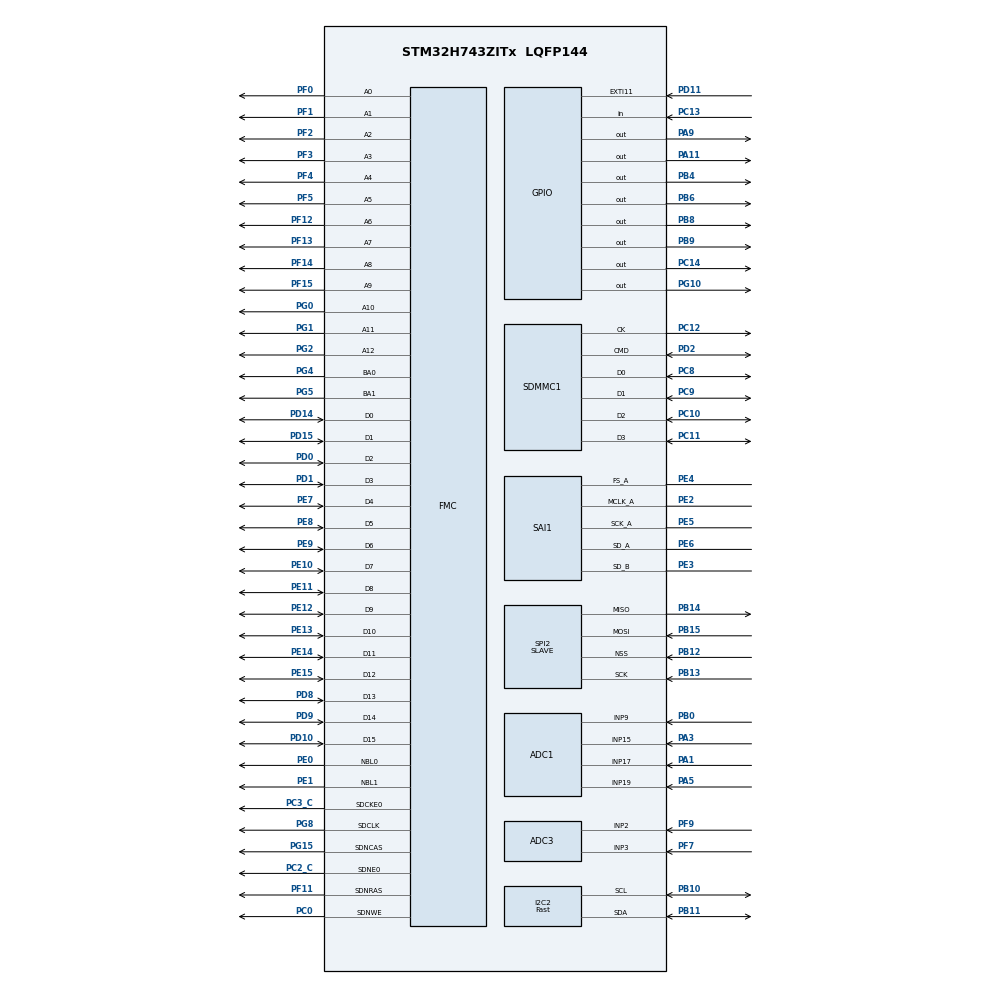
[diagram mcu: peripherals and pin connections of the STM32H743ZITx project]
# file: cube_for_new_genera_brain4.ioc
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Bdma.ADC3.0.PeriphInc=DMA_PINC_DISABLE
Bdma.Request0=ADC3
PC10.GPIO_PuPd=GPIO_PULLUP
FATFS._USE_LFN=1
FMC.SDClockPeriod1=FMC_SDRAM_CLOCK_PERIOD_3
SH.FMC_A0.0=FMC_A0,13b-sda1
FATFS0.BSP.api=Unknown
PG8.Signal=FMC_SDCLK
PG0.Signal=FMC_A10
RCC.PLLFRACN=0
PC3_C.Mode=SdramChipSelect1_1
ADC1.Rank-17\#ChannelRegularConversion=2
SAI1.Instance-SAI_A_MasterWithClock=SAI$Index_Block_A
Dma.SPI2_TX.4.RequestNumber=1
SH.FMC_D5_DA5.0=FMC_D5,sd-16b-d1
Dma.SPI2_RX.1.Mode=DMA_CIRCULAR
Bdma.ADC3.0.Instance=BDMA_Channel0
Dma.SPI2_TX.4.PeriphDataAlignment=DMA_PDATAALIGN_BYTE
SH.FMC_D9_DA9.0=FMC_D9,sd-16b-d1
Dma.SPI2_RX.1.PeriphDataAlignment=DMA_PDATAALIGN_BYTE
ADC1.Offset-17\#ChannelRegularConversion=32768
PF7.Signal=ADC3_INP3
SH.FMC_SDNWE.0=FMC_SDNWE,13b-sda1
Bdma.ADC3.0.SignalID=NONE
RCC.ADCCLockSelection=RCC_ADCCLKSOURCE_CLKP
SH.FMC_D11_DA11.0=FMC_D11,sd-16b-d1
SAI1.BasicProtocol-SAI_B_SyncSlave=SAI_I2S_STANDARD
I2C2.I2C_Speed_Mode=I2C_Fast
PB6.Signal=GPIO_Output
Dma.ADC1.0.Direction=DMA_PERIPH_TO_MEMORY
PD0.Signal=FMC_D2_DA2
SAI1.AudioMode-SAI_A_MasterWithClock=SAI_MODEMASTER_TX
PD8.Signal=FMC_D13_DA13
PE1.Signal=FMC_NBL1
Dma.ADC1.0.MemDataAlignment=DMA_MDATAALIGN_WORD
FATFS0.BSP.ip=GPIO
FMC.SelfRefreshTime1=4
Dma.SPI2_TX.4.EventEnable=DISABLE
Dma.SPI2_RX.1.FIFOMode=DMA_FIFOMODE_ENABLE
ADC1.Channel-19\#ChannelRegularConversion=ADC_CHANNEL_15
RCC.SAI1CLockSelection=RCC_SAI1CLKSOURCE_PLL2
PE9.Signal=FMC_D6_DA6
ADC1.OffsetNumber-19\#ChannelRegularConversion=ADC_OFFSET_NONE
Dma.SAI1_B.3.Direction=DMA_PERIPH_TO_MEMORY
SH.FMC_A2.0=FMC_A2,13b-sda1
PB14.Mode=Full_Duplex_Slave
PC9.Mode=SD_4_bits_Wide_bus
SH.FMC_D1_DA1.0=FMC_D1,sd-16b-d1
Mcu.Package=LQFP144
PB9.Signal=GPIO_Output
SAI1.AudioFrequency-SAI_A_MasterWithClock=SAI_AUDIO_FREQUENCY_48K
Dma.SAI1_B.3.Instance=DMA1_Stream2
SPI2.Mode=SPI_MODE_SLAVE
ADC1.OversamplingMode=ENABLE
RCC.PLL3FRACN=0
Dma.SAI1_A.2.PeriphBurst=DMA_PBURST_SINGLE
Dma.SPI2_RX.1.Instance=DMA1_Stream3
FMC.WriteRecoveryTime1=2
PC11.Mode=SD_4_bits_Wide_bus
FMC.RowCycleDelay1=6
PB13.Mode=Full_Duplex_Slave
ADC3.OffsetNumber-2\#ChannelRegularConversion=ADC_OFFSET_NONE
ADC1.EOCSelection=ADC_EOC_SEQ_CONV
PD15.Signal=FMC_D1_DA1
ADC1.SamplingTime-19\#ChannelRegularConversion=ADC_SAMPLETIME_32CYCLES_5
PC8.GPIO_Mode=GPIO_MODE_AF_PP
Dma.SPI2_TX.4.SignalID=NONE
FATFS0.BSP.STBoard=false
SH.FMC_A4.0=FMC_A4,13b-sda1
ADC3.OffsetNumber-1\#ChannelRegularConversion=ADC_OFFSET_NONE
Dma.SPI2_TX.4.Direction=DMA_MEMORY_TO_PERIPH
ADC1.Offset-18\#ChannelRegularConversion=32768
SAI1.MClockEnable-SAI_A_MasterWithClock=SAI_MASTERCLOCK_ENABLE
PG5.Signal=FMC_A15_BA1
SH.FMC_D10_DA10.0=FMC_D10,sd-16b-d1
PC13.Signal=GPIO_Input
FATFS0.BSP.mode=Input
Dma.SPI2_TX.4.FIFOThreshold=DMA_FIFO_THRESHOLD_1QUARTERFULL
SAI1.ErrorAudioFreq-SAI_A_MasterWithClock=-0.01 %
Dma.SPI2_TX.4.SyncSignalID=NONE
Dma.SAI1_A.2.SyncRequestNumber=1
Dma.SAI1_A.2.MemInc=DMA_MINC_ENABLE
SH.ADCx_INP9.0=ADC1_INP9,IN9-Single-Ended
Dma.SPI2_RX.1.SyncSignalID=NONE
Dma.SAI1_A.2.PeriphInc=DMA_PINC_DISABLE
Bdma.ADC3.0.SyncSignalID=NONE
PD10.Signal=FMC_D15_DA15
PC10.GPIO_Mode=GPIO_MODE_AF_PP
Dma.SPI2_TX.4.SyncEnable=DISABLE
ADC1.Channel-18\#ChannelRegularConversion=ADC_CHANNEL_17
Dma.ADC1.0.Priority=DMA_PRIORITY_HIGH
PB13.GPIO_Speed=GPIO_SPEED_FREQ_HIGH
Dma.SAI1_A.2.MemDataAlignment=DMA_MDATAALIGN_WORD
SAI1.VirtualMode-SAI_A_MasterWithClock=VM_MASTER
VP_SAI1_VP_$IpInstance_SAIB_SAI_BASIC.Mode=SAI_B_BASIC
PB14.Signal=SPI2_MISO
PA5.Signal=ADCx_INP19
PC12.Mode=SD_4_bits_Wide_bus
FMC.ReadBurst1=FMC_SDRAM_RBURST_ENABLE
SH.FMC_A6.0=FMC_A6,13b-sda1
PE14.Signal=FMC_D11_DA11
PE6.Mode=SAI_A_MasterWithClock
PC9.GPIO_PuPd=GPIO_PULLUP
SAI1.FIFOThreshold-SAI_A_MasterWithClock=SAI_FIFOTHRESHOLD_FULL
PF13.Signal=FMC_A7
PC8.Mode=SD_4_bits_Wide_bus
PC8.GPIO_PuPd=GPIO_PULLUP
ADC3.Rank-1\#ChannelRegularConversion=1
ADC1.Rank-16\#ChannelRegularConversion=1
ADC1.master=1
Bdma.ADC3.0.MemInc=DMA_MINC_ENABLE
Dma.ADC1.0.RequestNumber=1
Dma.SAI1_B.3.SignalID=NONE
ProjectManager.HeapSize=0x3000
ADC3.EOCSelection=ADC_EOC_SEQ_CONV
SAI1.VirtualProtocol-SAI_B_BASIC=VM_BASIC_PROTOCOL
NVIC.PriorityGroup=NVIC_PRIORITYGROUP_4
ADC1.ConversionDataManagement=ADC_CONVERSIONDATA_DMA_CIRCULAR
PE3.Signal=SAI1_SD_B
PF4.Signal=FMC_A4
PD2.Signal=SDMMC1_CMD
ADC1.SamplingTime-18\#ChannelRegularConversion=ADC_SAMPLETIME_32CYCLES_5
Dma.SPI2_RX.1.MemInc=DMA_MINC_ENABLE
FATFS0.BSP.name=Detect_SDIO
Mcu.Family=STM32H7
SPI2.VirtualNSS=VM_NSSHARD
SH.FMC_A8.0=FMC_A8,13b-sda1
ADC1.Overrun=ADC_OVR_DATA_PRESERVED
ADC1.ContinuousConvMode=ENABLE
SH.FMC_D14_DA14.0=FMC_D14,sd-16b-d1
PH0-OSC_IN\ (PH0).Signal=RCC_OSC_IN
PG2.Signal=FMC_A12
ADC1.Channel-17\#ChannelRegularConversion=ADC_CHANNEL_19
Dma.ADC1.0.Polarity=HAL_DMAMUX_REQ_GEN_RISING
SAI1.VirtualProtocol-SAI_A_BASIC=VM_BASIC_PROTOCOL
PE2.GPIO_Speed=GPIO_SPEED_FREQ_VERY_HIGH
PD2.GPIO_Mode=GPIO_MODE_AF_PP
RCC.PLL2FRACN=0
SH.FMC_A14_BA0.0=FMC_BA0,FourSdramBanks1
SH.FMC_A11.0=FMC_A11,13b-sda1
PB15.Signal=SPI2_MOSI
Bdma.ADC3.0.SyncPolarity=HAL_DMAMUX_SYNC_NO_EVENT
PG15.Signal=FMC_SDNCAS
Dma.SPI2_RX.1.Direction=DMA_PERIPH_TO_MEMORY
ADC3.Rank-2\#ChannelRegularConversion=2
NVIC.BDMA_Channel0_IRQn=true\:0\:0\:false\:false\:true\:false\:true
PC11.GPIO_PuPd=GPIO_PULLUP
SAI1.VirtualMode-SAI_B_SyncSlave=VM_SLAVE
ADC1.Offset-19\#ChannelRegularConversion=32768
SH.FMC_NBL1.0=FMC_NBL1,Sd2ByteEnable1
PH1-OSC_OUT\ (PH1).Mode=HSE-External-Oscillator
FMC.ExitSelfRefreshDelay1=6
Dma.ADC1.0.PeriphBurst=DMA_PBURST_SINGLE
PF9.Mode=IN2-Single-Ended
PF11.Signal=FMC_SDNRAS
PC13.GPIO_PuPd=GPIO_PULLDOWN
SAI1.InitProtocol-SAI_A_MasterWithClock=Enable
Dma.SAI1_A.2.EventEnable=DISABLE
Dma.SAI1_A.2.Direction=DMA_MEMORY_TO_PERIPH
PB12.Mode=NSS_Signal_Hard_Input
ADC1.SamplingTime-17\#ChannelRegularConversion=ADC_SAMPLETIME_32CYCLES_5
Dma.SPI2_RX.1.FIFOThreshold=DMA_FIFO_THRESHOLD_HALFFULL
Dma.Request2=SAI1_A
Dma.Request1=SPI2_RX
Dma.Request4=SPI2_TX
Dma.Request3=SAI1_B
NVIC.DMA1_Stream0_IRQn=true\:1\:0\:true\:false\:true\:false\:true
PE7.Signal=FMC_D4_DA4
Dma.Request0=ADC1
PA3.Signal=ADCx_INP15
Dma.SAI1_B.3.EventEnable=DISABLE
ADC1.OffsetNumber-17\#ChannelRegularConversion=ADC_OFFSET_NONE
Dma.SAI1_B.3.MemInc=DMA_MINC_ENABLE
PC11.Signal=SDMMC1_D3
ADC1.Rank-18\#ChannelRegularConversion=3
PC8.Signal=SDMMC1_D0
Dma.SAI1_A.2.Instance=DMA1_Stream1
PC10.Mode=SD_4_bits_Wide_bus
Dma.SPI2_TX.4.SyncRequestNumber=1
PD9.Signal=FMC_D14_DA14
SAI1.FIFOThreshold-SAI_B_SyncSlave=SAI_FIFOTHRESHOLD_FULL
PH1-OSC_OUT\ (PH1).Signal=RCC_OSC_OUT
FATFS0.BSP.instance=PC13
Dma.SAI1_A.2.Priority=DMA_PRIORITY_LOW
Dma.SAI1_B.3.SyncPolarity=HAL_DMAMUX_SYNC_NO_EVENT
SAI1.RealAudioFreq-SAI_A_MasterWithClock=47.991 KHz
Dma.ADC1.0.PeriphDataAlignment=DMA_PDATAALIGN_WORD
PC9.GPIO_Mode=GPIO_MODE_AF_PP
SH.FMC_D13_DA13.0=FMC_D13,sd-16b-d1
SAI1.BasicDataSize-SAI_B_SyncSlave=SAI_PROTOCOL_DATASIZE_32BIT
RCC.USBFreq_Value=48000000
PA1.Signal=ADC1_INP17
PD2.Mode=SD_4_bits_Wide_bus
board=custom
PB15.Mode=Full_Duplex_Slave
Dma.SPI2_RX.1.Priority=DMA_PRIORITY_VERY_HIGH
PE5.Mode=SAI_A_MasterWithClock
RCC.ADCFreq_Value=64000000
SH.FMC_D12_DA12.0=FMC_D12,sd-16b-d1
PF1.Signal=FMC_A1
ADC1.NbrOfConversion=4
PE0.Signal=FMC_NBL0
PE12.Signal=FMC_D9_DA9
ADC1.Offset-16\#ChannelRegularConversion=32768
RCC.SYSCLKFreq_VALUE=480000000
Dma.ADC1.0.MemInc=DMA_MINC_ENABLE
PC3_C.Signal=FMC_SDCKE0
PE5.GPIO_Speed=GPIO_SPEED_FREQ_HIGH
NVIC.DMA1_Stream3_IRQn=true\:2\:0\:true\:false\:true\:false\:true
CORTEX_M7.CPU_DCache=Enabled
PD2.GPIO_Speed_High_Default=GPIO_SPEED_FREQ_MEDIUM
ADC3.NbrOfConversionFlag=1
PB12.Signal=SPI2_NSS
PB4\ (NJTRST).Signal=GPIO_Output
SH.FMC_D7_DA7.0=FMC_D7,sd-16b-d1
FMC.RCDDelay1=2
SPI2.VirtualType=VM_SLAVE
PB10.Mode=I2C
VP_FATFS_VS_SDIO.Mode=SDIO
RCC.PLL2_VCI_Range-AdvancedSettings=RCC_PLL2VCIRANGE_1
PG4.Signal=FMC_A14_BA0
NVIC.DMA1_Stream2_IRQn=true\:0\:0\:false\:false\:true\:false\:true
PC12.Signal=SDMMC1_CK
Dma.SAI1_B.3.RequestNumber=1
FMC.LoadToActiveDelay1=2
Dma.SAI1_B.3.SyncSignalID=NONE
PB13.Signal=SPI2_SCK
RCC.SYSCLKSource=RCC_SYSCLKSOURCE_PLLCLK
SH.FMC_A15_BA1.0=FMC_BA1,FourSdramBanks1
RCC.SPI123CLockSelection=RCC_SPI123CLKSOURCE_PLL2
Dma.SPI2_TX.4.PeriphInc=DMA_PINC_DISABLE
NVIC.SDMMC1_IRQn=true\:7\:0\:true\:false\:true\:true\:true
PA14\ (JTCK/SWCLK).Signal=DEBUG_JTCK-SWCLK
PC10.GPIO_Speed_High_Default=GPIO_SPEED_FREQ_MEDIUM
PE2.Mode=SAI_A_MasterWithClock
Dma.SPI2_RX.1.RequestNumber=1
PE5.Signal=SAI1_SCK_A
Bdma.ADC3.0.PeriphDataAlignment=DMA_PDATAALIGN_WORD
Dma.SPI2_TX.4.Polarity=HAL_DMAMUX_REQ_GEN_RISING
FATFS0.BSP.i2caddr=0
ADC3.SamplingTime-2\#ChannelRegularConversion=ADC_SAMPLETIME_32CYCLES_5
RCC.DIVM2=25
RCC.DIVM1=5
Dma.ADC1.0.PeriphInc=DMA_PINC_DISABLE
ADC3.ContinuousConvMode=ENABLE
PE2.Signal=SAI1_MCLK_A
PA14\ (JTCK/SWCLK).Mode=Trace_Asynchronous_SW
PF3.Signal=FMC_A3
ADC3.Channel-2\#ChannelRegularConversion=ADC_CHANNEL_2
PE10.Signal=FMC_D7_DA7
Dma.SPI2_RX.1.SyncRequestNumber=1
Bdma.ADC3.0.Priority=DMA_PRIORITY_HIGH
ADC1.EnableInjectedConversion=DISABLE
FATFS0.BSP.solution=PC13
SH.FMC_A1.0=FMC_A1,13b-sda1
Dma.SAI1_A.2.FIFOMode=DMA_FIFOMODE_ENABLE
SH.FMC_SDCLK.0=FMC_SDCLK,13b-sda1
RCC.APB4Freq_Value=120000000
PF14.Signal=FMC_A8
Dma.ADC1.0.FIFOMode=DMA_FIFOMODE_ENABLE
PC12.GPIO_PuPd=GPIO_PULLUP
Dma.SPI2_RX.1.SyncPolarity=HAL_DMAMUX_SYNC_NO_EVENT
FMC.ColumnBitsNumber1=FMC_SDRAM_COLUMN_BITS_NUM_9
PE6.GPIO_Speed=GPIO_SPEED_FREQ_HIGH
PH0-OSC_IN\ (PH0).Mode=HSE-External-Oscillator
SH.FMC_D3_DA3.0=FMC_D3,sd-16b-d1
Dma.ADC1.0.EventEnable=DISABLE
ADC3.OffsetSignedSaturation-2\#ChannelRegularConversion=DISABLE
Bdma.ADC3.0.Polarity=HAL_DMAMUX_REQ_GEN_RISING
Dma.ADC1.0.Instance=DMA1_Stream0
Dma.SPI2_RX.1.PeriphBurst=DMA_PBURST_SINGLE
PD2.GPIO_PuPd=GPIO_PULLUP
VP_SAI1_VP_$IpInstance_SAIA_SAI_BASIC.Mode=SAI_A_BASIC
Dma.ADC1.0.SyncRequestNumber=1
Dma.SPI2_TX.4.Priority=DMA_PRIORITY_LOW
Bdma.ADC3.0.RequestNumber=1
PD1.Signal=FMC_D3_DA3
RCC.DIVP2=7
ADC1.ExternalTrigConvEdge=ADC_EXTERNALTRIGCONVEDGE_NONE
PC0.Signal=FMC_SDNWE
Dma.SAI1_B.3.Priority=DMA_PRIORITY_HIGH
Bdma.ADC3.0.SyncEnable=DISABLE
PG10.Signal=GPIO_Output
SH.FMC_A3.0=FMC_A3,13b-sda1
FMC.CASLatency1=FMC_SDRAM_CAS_LATENCY_2
PB11.Mode=I2C
PB14.GPIO_Speed=GPIO_SPEED_FREQ_HIGH
Bdma.ADC3.0.Direction=DMA_PERIPH_TO_MEMORY
SH.FMC_D15_DA15.0=FMC_D15,sd-16b-d1
Dma.ADC1.0.SignalID=NONE
PA9.Signal=GPIO_Output
Dma.SAI1_B.3.Polarity=HAL_DMAMUX_REQ_GEN_RISING
RCC.DIVN2=344
RCC.DIVN1=192
Dma.SAI1_B.3.PeriphInc=DMA_PINC_DISABLE
PC2_C.Mode=SdramChipSelect1_1
ADC3.NbrOfConversion=2
Dma.SAI1_B.3.MemBurst=DMA_MBURST_SINGLE
Dma.SPI2_TX.4.MemBurst=DMA_MBURST_SINGLE
PB10.Signal=I2C2_SCL
FATFS.BSP.number=1
RCC.USBCLockSelection=RCC_USBCLKSOURCE_HSI48
Dma.SPI2_RX.1.SyncEnable=DISABLE
PA1.Mode=IN17-Single-Ended
PE15.Signal=FMC_D12_DA12
PE8.Signal=FMC_D5_DA5
Dma.SAI1_A.2.SyncEnable=DISABLE
Dma.SPI2_TX.4.MemDataAlignment=DMA_MDATAALIGN_BYTE
Bdma.ADC3.0.MemDataAlignment=DMA_MDATAALIGN_WORD
PC11.GPIO_Mode=GPIO_MODE_AF_PP
SH.FMC_SDNCAS.0=FMC_SDNCAS,13b-sda1
ADC3.Channel-1\#ChannelRegularConversion=ADC_CHANNEL_3
PC12.GPIO_Speed_High_Default=GPIO_SPEED_FREQ_MEDIUM
PC8.GPIO_Speed_High_Default=GPIO_SPEED_FREQ_MEDIUM
PE3.GPIO_Speed=GPIO_SPEED_FREQ_HIGH
PD11.Signal=GPXTI11
SH.FMC_A5.0=FMC_A5,13b-sda1
Dma.SAI1_A.2.PeriphDataAlignment=DMA_PDATAALIGN_WORD
PA11.Signal=GPIO_Output
ADC1.OffsetNumber-16\#ChannelRegularConversion=ADC_OFFSET_NONE
PF9.Signal=ADC3_INP2
PB3\ (JTDO/TRACESWO).Mode=Trace_Asynchronous_SW
ADC3.OffsetSignedSaturation-1\#ChannelRegularConversion=DISABLE
ADC1.EnableRegularConversion=ENABLE
SH.ADCx_INP19.0=ADC1_INP19,IN19-Single-Ended
SPI2.DataSize=SPI_DATASIZE_8BIT
PB0.Signal=ADCx_INP9
Dma.SAI1_B.3.FIFOThreshold=DMA_FIFO_THRESHOLD_1QUARTERFULL
PA13\ (JTMS/SWDIO).Signal=DEBUG_JTMS-SWDIO
Dma.SAI1_B.3.SyncEnable=DISABLE
Dma.SPI2_TX.4.MemInc=DMA_MINC_ENABLE
ADC1.RightBitShift=ADC_RIGHTBITSHIFT_1
Dma.SPI2_RX.1.MemDataAlignment=DMA_MDATAALIGN_BYTE
RCC.CortexFreq_Value=480000000
PC14-OSC32_IN\ (OSC32_IN).GPIO_PuPd=GPIO_PULLDOWN
RCC.HPRE=RCC_HCLK_DIV2
PC10.Signal=SDMMC1_D2
I2C2.Timing=0x00B03FDB
SH.FMC_NBL0.0=FMC_NBL0,Sd2ByteEnable1
SH.FMC_D6_DA6.0=FMC_D6,sd-16b-d1
SDMMC1.ClockDiv=16
Dma.ADC1.0.FIFOThreshold=DMA_FIFO_THRESHOLD_HALFFULL
Dma.SPI2_RX.1.Polarity=HAL_DMAMUX_REQ_GEN_RISING
Dma.SPI2_RX.1.MemBurst=DMA_MBURST_SINGLE
Dma.SPI2_TX.4.Mode=DMA_CIRCULAR
Dma.SAI1_B.3.SyncRequestNumber=1
PB11.Signal=I2C2_SDA
NVIC.DMA1_Stream4_IRQn=true\:0\:0\:false\:false\:true\:false\:true
ProjectManager.StackSize=0x3000
Dma.SAI1_B.3.PeriphDataAlignment=DMA_PDATAALIGN_WORD
SH.FMC_A7.0=FMC_A7,13b-sda1
FMC.BankMapConfig=FMC_SWAPBMAP_SDRAM_SRAM
RCC.HCLKFreq_Value=240000000
Dma.SAI1_A.2.RequestNumber=1
PF12.Signal=FMC_A6
PC9.GPIO_Speed_High_Default=GPIO_SPEED_FREQ_MEDIUM
PC2_C.Signal=FMC_SDNE0
SH.FMC_A10.0=FMC_A10,13b-sda1
ADC3.SamplingTime-1\#ChannelRegularConversion=ADC_SAMPLETIME_32CYCLES_5
SH.FMC_D8_DA8.0=FMC_D8,sd-16b-d1
FMC.RPDelay1=2
Dma.SPI2_TX.4.SyncPolarity=HAL_DMAMUX_SYNC_NO_EVENT
SH.FMC_D2_DA2.0=FMC_D2,sd-16b-d1
PE13.Signal=FMC_D10_DA10
PE4.GPIO_Speed=GPIO_SPEED_FREQ_HIGH
ADC1.Rank-19\#ChannelRegularConversion=4
NVIC.SPI2_IRQn=true\:3\:0\:true\:false\:true\:false\:true
PE4.Mode=SAI_A_MasterWithClock
SH.FMC_SDNRAS.0=FMC_SDNRAS,13b-sda1
PE4.Signal=SAI1_FS_A
Dma.SPI2_TX.4.PeriphBurst=DMA_PBURST_SINGLE
Dma.SAI1_A.2.FIFOThreshold=DMA_FIFO_THRESHOLD_1QUARTERFULL
FATFS._USE_LABEL=1
RCC.APB3Freq_Value=120000000
SH.FMC_D0_DA0.0=FMC_D0,sd-16b-d1
RCC.D1PPRE=RCC_APB3_DIV2
RCC.SDMMC1CLockSelection=RCC_SDMMCCLKSOURCE_PLL2
SH.FMC_A9.0=FMC_A9,13b-sda1
Bdma.ADC3.0.SyncRequestNumber=1
SH.FMC_D4_DA4.0=FMC_D4,sd-16b-d1
ADC3.ClockPrescaler=ADC_CLOCK_ASYNC_DIV4
PF5.Signal=FMC_A5
Dma.ADC1.0.MemBurst=DMA_MBURST_SINGLE
Dma.SAI1_B.3.MemDataAlignment=DMA_MDATAALIGN_WORD
SH.ADCx_INP15.0=ADC1_INP15,IN15-Single-Ended
SPI2.Direction=SPI_DIRECTION_2LINES
PF0.Signal=FMC_A0
SAI1.BasicProtocol-SAI_A_MasterWithClock=SAI_I2S_STANDARD
PE3.Mode=SAI_B_SyncSlave
Dma.SAI1_A.2.MemBurst=DMA_MBURST_SINGLE
Dma.SAI1_A.2.Mode=DMA_CIRCULAR
SH.FMC_A12.0=FMC_A12,13b-sda1
RCC.PLLSourceVirtual=RCC_PLLSOURCE_HSE
ADC3.DiscontinuousConvMode=DISABLE
CORTEX_M7.CPU_ICache=Enabled
PA13\ (JTMS/SWDIO).Mode=Trace_Asynchronous_SW
ADC1.SamplingTime-16\#ChannelRegularConversion=ADC_SAMPLETIME_32CYCLES_5
PG1.Signal=FMC_A11
RCC.D2PPRE2=RCC_APB2_DIV2
RCC.D2PPRE1=RCC_APB1_DIV2
NVIC.DMA1_Stream1_IRQn=true\:0\:0\:false\:false\:true\:false\:true
VP_RNG_VS_RNG.Mode=RNG_Activate
Dma.SPI2_RX.1.EventEnable=DISABLE
Dma.SAI1_B.3.FIFOMode=DMA_FIFOMODE_ENABLE
PF7.Mode=IN3-Single-Ended
Dma.SAI1_A.2.SignalID=NONE
Dma.SPI2_TX.4.Instance=DMA1_Stream4
PB3\ (JTDO/TRACESWO).Signal=DEBUG_JTDO-SWO
ProjectManager.TargetToolchain=STM32CubeIDE
Dma.SAI1_A.2.SyncPolarity=HAL_DMAMUX_SYNC_NO_EVENT
Bdma.ADC3.0.EventEnable=DISABLE
Dma.ADC1.0.Mode=DMA_CIRCULAR
Dma.ADC1.0.SyncSignalID=NONE
Bdma.RequestsNb=1
ADC3.OversamplingMode=DISABLE
PC11.GPIO_Speed_High_Default=GPIO_SPEED_FREQ_MEDIUM
PF2.Signal=FMC_A2
PE11.Signal=FMC_D8_DA8
Dma.SPI2_TX.4.FIFOMode=DMA_FIFOMODE_ENABLE
PB12.GPIO_Speed=GPIO_SPEED_FREQ_HIGH
Bdma.ADC3.0.Mode=DMA_CIRCULAR
ADC1.NbrOfDiscConversion=4
Dma.SPI2_RX.1.SignalID=NONE
Dma.ADC1.0.SyncPolarity=HAL_DMAMUX_SYNC_NO_EVENT
FATFS.USE_DMA_CODE_SD=0
SAI1.BasicDataSize-SAI_A_MasterWithClock=SAI_PROTOCOL_DATASIZE_32BIT
RCC.APB2Freq_Value=120000000
PB15.GPIO_Speed=GPIO_SPEED_FREQ_HIGH
ADC1.Channel-16\#ChannelRegularConversion=ADC_CHANNEL_9
PF15.Signal=FMC_A9
PE6.Signal=SAI1_SD_A
Mcu.Name=STM32H743ZITx
ADC3.ConversionDataManagement=ADC_CONVERSIONDATA_DMA_CIRCULAR
Dma.SPI2_RX.1.PeriphInc=DMA_PINC_DISABLE
RCC.PLL3_VCI_Range-AdvancedSettings=RCC_PLL3VCIRANGE_0
PD14.Signal=FMC_D0_DA0
PC14-OSC32_IN\ (OSC32_IN).Signal=GPIO_Output
SAI1.Instance-SAI_B_SyncSlave=SAI$Index_Block_B
Dma.ADC1.0.SyncEnable=DISABLE
Dma.SAI1_A.2.SyncSignalID=NONE
ADC1.NbrOfConversionFlag=1
ADC1.OffsetNumber-18\#ChannelRegularConversion=ADC_OFFSET_NONE
PB8.Signal=GPIO_Output
Dma.SAI1_B.3.Mode=DMA_CIRCULAR
RCC.D3PPRE=RCC_APB4_DIV2
PC9.Signal=SDMMC1_D1
Dma.SAI1_B.3.PeriphBurst=DMA_PBURST_SINGLE
RCC.APB1Freq_Value=120000000
SAI1.InitProtocol-SAI_B_SyncSlave=Enable
ADC1.ClockPrescaler=ADC_CLOCK_ASYNC_DIV4
Dma.SAI1_A.2.Polarity=HAL_DMAMUX_REQ_GEN_RISING

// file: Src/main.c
/* USER CODE BEGIN Header */
/**
  ******************************************************************************
  * @file           : main.c
  * @brief          : Main program body
  ******************************************************************************
  * @attention
  *
  * <h2><center>&copy; Copyright (c) 2020 STMicroelectronics.
  * All rights reserved.</center></h2>
  *
  * This software component is licensed by ST under Ultimate Liberty license
  * SLA0044, the "License"; You may not use this file except in compliance with
  * the License. You may obtain a copy of the License at:
  *                             www.st.com/SLA0044
  *
  ******************************************************************************
  */
/* USER CODE END Header */
#include "main.h"
#include "adc.h"
#include "bdma.h"
#include "dma.h"
#include "fatfs.h"
#include "i2c.h"
#include "rng.h"
#include "sai.h"
#include "sdmmc.h"
#include "spi.h"
#include "gpio.h"
#include "fmc.h"

/* USER CODE BEGIN Includes */
#include <stdio.h>
#include <stdlib.h>
#include <string.h>
#include "leaf.h"
#include "codec.h"
#define SDRECORD 0
#define SAMPLE_RATE 48000
/* USER CODE END Includes */

/* USER CODE BEGIN PV */
uint8_t SPI_TX[32] __ATTR_RAM_D2;
uint8_t SPI_RX[32] __ATTR_RAM_D2;

//uint8_t SPI_PLUCK_TX[22] __ATTR_RAM_D2;

uint8_t counter;
int SDReady = 0;
uint64_t SDWriteIndex = 0;
FRESULT res;
  FATFS MMCFatFs;
  FIL myFile;
  FATFS fs;
  DSTATUS statusH;

int finishSD = 0;

int32_t audioOutBuffer[AUDIO_BUFFER_SIZE] __ATTR_RAM_D2;
int32_t audioInBuffer[AUDIO_BUFFER_SIZE] __ATTR_RAM_D2;
int32_t ADC_values[NUM_ADC_CHANNELS * ADC_BUFFER_SIZE] __ATTR_RAM_D2;
int32_t ADC_values2[NUM_ADC_CHANNELS2 * ADC_BUFFER_SIZE] __ATTR_RAM_D3;

#define FILTER_ORDER 2
#define ATODB_TABLE_SIZE 25000
#define ATODB_TABLE_SIZE_MINUS_ONE 24999

#define MEDIUM_MEM_SIZE 300000
char mediumMemory[MEDIUM_MEM_SIZE] __ATTR_RAM_D1;

tMempool mediumPool;
#define LARGE_MEM_SIZE_TWOBYTE 16777216
uint8_t largeMemory[LARGE_MEM_SIZE] __ATTR_SDRAM;
uint memoryPointer = 0;

int smoothedInt[NUM_STRINGS];
int smoothedInt2[NUM_STRINGS];
int dbSmoothedInt[NUM_STRINGS];
int tempAbsInt[NUM_STRINGS];
float atodbTable[ATODB_TABLE_SIZE];
int storedMaximums[NUM_STRINGS] = {5000.0f, 5000.0f, 5000.0f, 5000.0f};
float storedMaxFloats[NUM_STRINGS];
volatile uint16_t stringPositions[NUM_ADC_CHANNELS];
volatile uint16_t stringTouchRH[NUM_ADC_CHANNELS];
volatile uint16_t stringTouchLH[NUM_ADC_CHANNELS];
volatile int didPlucked[NUM_ADC_CHANNELS];
volatile int stringSounding[NUM_ADC_CHANNELS];

int howManyFrames = 48000;
int brokedIt = 0;
int didPlucked2[4];
int pluckDelay[4];
int pluckValues[4];

float Dsmoothed;
float Dsmoothed2;
float dbSmoothed2;

int armed[NUM_STRINGS] = {0,0,0,0};
float prevdbSmoothed2[NUM_STRINGS];
int threshOut = 0;
int stringMaxes[NUM_STRINGS] = {0,0,0,0};
int downCounter[NUM_STRINGS];
int armedCounter[NUM_STRINGS];
float slopeStorage[NUM_STRINGS];

tHighpass opticalHighpass[NUM_ADC_CHANNELS][FILTER_ORDER];
tHighpass EMHighpass[2];
tVZFilter opticalLowpass[NUM_ADC_CHANNELS][FILTER_ORDER];
tSlide fastSlide[NUM_ADC_CHANNELS];
tSlide slowSlide[NUM_ADC_CHANNELS];
tThreshold threshold[NUM_ADC_CHANNELS];
LEAF leaf;
/* USER CODE END PV */

void SystemClock_Config(void);
void PeriphCommonClock_Config(void);
/* USER CODE BEGIN PFP */
void MPU_Conf(void);
void SDRAM_Initialization_sequence(void);
static void FS_FileOperations(void);
float randomNumber(void);
/* USER CODE END PFP */

int main(void)
{
  /* USER CODE BEGIN 1 */
  MPU_Conf();
  /* USER CODE END 1 */

  /* Enable I-Cache---------------------------------------------------------*/
  SCB_EnableICache();

  /* Enable D-Cache---------------------------------------------------------*/
  SCB_EnableDCache();

  /* MCU Configuration--------------------------------------------------------*/

  /* Reset of all peripherals, Initializes the Flash interface and the Systick. */
  HAL_Init();

  /* Configure the system clock */
  SystemClock_Config();

/* Configure the peripherals common clocks */
  PeriphCommonClock_Config();

  /* Initialize all configured peripherals */
  MX_GPIO_Init();
  MX_BDMA_Init();
  MX_DMA_Init();
  MX_FMC_Init();
  MX_SDMMC1_SD_Init();
  MX_FATFS_Init();
  MX_RNG_Init();
  MX_SPI2_Init();
  MX_ADC1_Init();
  MX_ADC3_Init();
  MX_SAI1_Init();
  MX_I2C2_Init();
  /* USER CODE BEGIN 2 */
  uint32_t tempFPURegisterVal = __get_FPSCR();
  tempFPURegisterVal |= (1<<24); // set the FTZ (flush-to-zero) bit in the FPU control register
  __set_FPSCR(tempFPURegisterVal);

  for (int i = 0; i < 32; i++)
  {
	  SPI_TX[i] = counter++;
  }

  //for (int i = 0; i < 22; i++)
  //{
	  //SPI_PLUCK_TX[i] = 0;
  //}
  //SPI_PLUCK_TX[0] = 254;//start message
  //SPI_PLUCK_TX[21] = 253;//end message

  //HAL_Delay(100);
  HAL_SPI_TransmitReceive_DMA(&hspi2, SPI_TX, SPI_RX, 32);

  HAL_GPIO_WritePin(GPIOC, GPIO_PIN_6, GPIO_PIN_SET);
  HAL_Delay(10);

  SDRAM_Initialization_sequence();

  HAL_SAI_Transmit_DMA(&hsai_BlockA1, (uint8_t *)&audioOutBuffer[0], AUDIO_BUFFER_SIZE);
  HAL_SAI_Receive_DMA(&hsai_BlockB1, (uint8_t *)&audioInBuffer[0], AUDIO_BUFFER_SIZE);
  AudioCodec_init(&hi2c2);

#if SDRECORD
 if(BSP_SD_IsDetected())
 {
   FS_FileOperations();
 }
#endif
LEAF_init(&leaf, SAMPLE_RATE, mediumMemory, MEDIUM_MEM_SIZE, &randomNumber);

for (int i = 0; i < NUM_ADC_CHANNELS; i++)
{
	tThreshold_init(&threshold[i],0.05f * (float)storedMaximums[i], 0.1f * (float)storedMaximums[i], &leaf);
	tSlide_init(&fastSlide[i],1.0f,500.0f, &leaf); //500
	tSlide_init(&slowSlide[i],1.0f,1000.0f, &leaf); //500

	storedMaxFloats[i] = (65535.0f / storedMaximums[i]);
	for (int j = 0; j < FILTER_ORDER; j++)
	{
		tVZFilter_init(&opticalLowpass[i][j], Lowpass, 6000.0f, 0.6f, &leaf); //1000
		tHighpass_init(&opticalHighpass[i][j], 100.0f, &leaf); //100
	}
	tHighpass_init(&EMHighpass[0], 50.0f, &leaf);
	tHighpass_init(&EMHighpass[1], 50.0f, &leaf);
}

LEAF_generate_atodb(atodbTable, ATODB_TABLE_SIZE);

 HAL_ADC_Start_DMA(&hadc1,(uint32_t*)&ADC_values,NUM_ADC_CHANNELS * ADC_BUFFER_SIZE);
 HAL_ADC_Start_DMA(&hadc3,(uint32_t*)&ADC_values2,NUM_ADC_CHANNELS2 * ADC_BUFFER_SIZE);
  /* USER CODE END 2 */

  /* Infinite loop */
  /* USER CODE BEGIN WHILE */
  while (1)
  {

	  //int tempIntGP = HAL_GPIO_ReadPin(GPIOC, GPIO_PIN_13);
	  //if (tempIntGP)
	  //{
		  //HAL_GPIO_WritePin(GPIOB, GPIO_PIN_4, GPIO_PIN_SET);
	  //}
	  //else

	  //{
		  //HAL_GPIO_WritePin(GPIOB, GPIO_PIN_4, GPIO_PIN_RESET);
	 // }
    /* USER CODE END WHILE */

  }
}

void SystemClock_Config(void)
{
  RCC_OscInitTypeDef RCC_OscInitStruct = {0};
  RCC_ClkInitTypeDef RCC_ClkInitStruct = {0};

  /** Supply configuration update enable
  */
  HAL_PWREx_ConfigSupply(PWR_LDO_SUPPLY);
  /** Configure the main internal regulator output voltage
  */
  __HAL_PWR_VOLTAGESCALING_CONFIG(PWR_REGULATOR_VOLTAGE_SCALE0);

  while(!__HAL_PWR_GET_FLAG(PWR_FLAG_VOSRDY)) {}
  /** Macro to configure the PLL clock source
  */
  __HAL_RCC_PLL_PLLSOURCE_CONFIG(RCC_PLLSOURCE_HSE);
  /** Initializes the RCC Oscillators according to the specified parameters
  * in the RCC_OscInitTypeDef structure.
  */
  RCC_OscInitStruct.OscillatorType = RCC_OSCILLATORTYPE_HSI48|RCC_OSCILLATORTYPE_HSI
                              |RCC_OSCILLATORTYPE_HSE;
  RCC_OscInitStruct.HSEState = RCC_HSE_ON;
  RCC_OscInitStruct.HSIState = RCC_HSI_DIV1;
  RCC_OscInitStruct.HSICalibrationValue = RCC_HSICALIBRATION_DEFAULT;
  RCC_OscInitStruct.HSI48State = RCC_HSI48_ON;
  RCC_OscInitStruct.PLL.PLLState = RCC_PLL_ON;
  RCC_OscInitStruct.PLL.PLLSource = RCC_PLLSOURCE_HSE;
  RCC_OscInitStruct.PLL.PLLM = 5;
  RCC_OscInitStruct.PLL.PLLN = 192;
  RCC_OscInitStruct.PLL.PLLP = 2;
  RCC_OscInitStruct.PLL.PLLQ = 2;
  RCC_OscInitStruct.PLL.PLLR = 2;
  RCC_OscInitStruct.PLL.PLLRGE = RCC_PLL1VCIRANGE_2;
  RCC_OscInitStruct.PLL.PLLVCOSEL = RCC_PLL1VCOWIDE;
  RCC_OscInitStruct.PLL.PLLFRACN = 0;
  if (HAL_RCC_OscConfig(&RCC_OscInitStruct) != HAL_OK)
  {
    Error_Handler();
  }
  /** Initializes the CPU, AHB and APB buses clocks
  */
  RCC_ClkInitStruct.ClockType = RCC_CLOCKTYPE_HCLK|RCC_CLOCKTYPE_SYSCLK
                              |RCC_CLOCKTYPE_PCLK1|RCC_CLOCKTYPE_PCLK2
                              |RCC_CLOCKTYPE_D3PCLK1|RCC_CLOCKTYPE_D1PCLK1;
  RCC_ClkInitStruct.SYSCLKSource = RCC_SYSCLKSOURCE_PLLCLK;
  RCC_ClkInitStruct.SYSCLKDivider = RCC_SYSCLK_DIV1;
  RCC_ClkInitStruct.AHBCLKDivider = RCC_HCLK_DIV2;
  RCC_ClkInitStruct.APB3CLKDivider = RCC_APB3_DIV2;
  RCC_ClkInitStruct.APB1CLKDivider = RCC_APB1_DIV2;
  RCC_ClkInitStruct.APB2CLKDivider = RCC_APB2_DIV2;
  RCC_ClkInitStruct.APB4CLKDivider = RCC_APB4_DIV2;

  if (HAL_RCC_ClockConfig(&RCC_ClkInitStruct, FLASH_LATENCY_4) != HAL_OK)
  {
    Error_Handler();
  }
}

void PeriphCommonClock_Config(void)
{
  RCC_PeriphCLKInitTypeDef PeriphClkInitStruct = {0};

  /** Initializes the peripherals clock
  */
  PeriphClkInitStruct.PeriphClockSelection = RCC_PERIPHCLK_SDMMC|RCC_PERIPHCLK_SAI1
                              |RCC_PERIPHCLK_SPI2|RCC_PERIPHCLK_CKPER;
  PeriphClkInitStruct.PLL2.PLL2M = 25;
  PeriphClkInitStruct.PLL2.PLL2N = 344;
  PeriphClkInitStruct.PLL2.PLL2P = 7;
  PeriphClkInitStruct.PLL2.PLL2Q = 2;
  PeriphClkInitStruct.PLL2.PLL2R = 2;
  PeriphClkInitStruct.PLL2.PLL2RGE = RCC_PLL2VCIRANGE_0;
  PeriphClkInitStruct.PLL2.PLL2VCOSEL = RCC_PLL2VCOWIDE;
  PeriphClkInitStruct.PLL2.PLL2FRACN = 0;
  PeriphClkInitStruct.SdmmcClockSelection = RCC_SDMMCCLKSOURCE_PLL2;
  PeriphClkInitStruct.CkperClockSelection = RCC_CLKPSOURCE_HSI;
  PeriphClkInitStruct.Sai1ClockSelection = RCC_SAI1CLKSOURCE_PLL2;
  PeriphClkInitStruct.Spi123ClockSelection = RCC_SPI123CLKSOURCE_PLL2;
  if (HAL_RCCEx_PeriphCLKConfig(&PeriphClkInitStruct) != HAL_OK)
  {
    Error_Handler();
  }
}

/* USER CODE BEGIN 4 */

float randomNumber(void) {

	uint32_t rand;
	HAL_RNG_GenerateRandomNumber(&hrng, &rand);
	float num = (float)rand * INV_TWO_TO_32;
	return num;
}

#define SDRAM_TIMEOUT ((uint32_t)0xFFFF)

#define SDRAM_MODEREG_BURST_LENGTH_1             ((uint16_t)0x0000)
#define SDRAM_MODEREG_BURST_LENGTH_2             ((uint16_t)0x0001)
#define SDRAM_MODEREG_BURST_LENGTH_4             ((uint16_t)0x0002)
#define SDRAM_MODEREG_BURST_LENGTH_8             ((uint16_t)0x0003)
#define SDRAM_MODEREG_BURST_TYPE_SEQUENTIAL      ((uint16_t)0x0000)
#define SDRAM_MODEREG_BURST_TYPE_INTERLEAVED     ((uint16_t)0x0008)
#define SDRAM_MODEREG_CAS_LATENCY_2              ((uint16_t)0x0020)
#define SDRAM_MODEREG_CAS_LATENCY_3              ((uint16_t)0x0030)
#define SDRAM_MODEREG_OPERATING_MODE_STANDARD    ((uint16_t)0x0000)
#define SDRAM_MODEREG_WRITEBURST_MODE_PROGRAMMED ((uint16_t)0x0000)
#define SDRAM_MODEREG_WRITEBURST_MODE_SINGLE     ((uint16_t)0x0200)

//#define SDRAM_REFRESH_COUNT                   	 ((uint32_t)956)// 7.9us in cycles of 8.333333ns + 20 cycles as recommended by datasheet page 866/3289 for STM32H743
#define SDRAM_REFRESH_COUNT                   	 ((uint32_t)0x0569)// 7.9us in cycles of 8.333333ns + 20 cycles as recommended by datasheet page 866/3289 for STM32H743
void SDRAM_Initialization_sequence(void)
{
    __IO uint32_t tmpmrd = 0;
    FMC_SDRAM_CommandTypeDef Command;
    /* Step 1: Configure a clock configuration enable command */
    Command.CommandMode = FMC_SDRAM_CMD_CLK_ENABLE;
    Command.CommandTarget = FMC_SDRAM_CMD_TARGET_BANK1;
    Command.AutoRefreshNumber = 1;
    Command.ModeRegisterDefinition = 0;

    /* Send the command */
    HAL_SDRAM_SendCommand(&hsdram1, &Command, SDRAM_TIMEOUT);

    /* Step 2: Insert 100 us minimum delay */
    /* Inserted delay is equal to 1 ms due to systick time base unit (ms) */
    HAL_Delay(1);

    /* Step 3: Configure a PALL (precharge all) command */
    Command.CommandMode = FMC_SDRAM_CMD_PALL;
    Command.CommandTarget = FMC_SDRAM_CMD_TARGET_BANK1;
    Command.AutoRefreshNumber = 1;
    Command.ModeRegisterDefinition = 0;

    /* Send the command */
    HAL_SDRAM_SendCommand(&hsdram1, &Command, SDRAM_TIMEOUT);

    /* Step 5: Program the external memory mode register */
    tmpmrd = (uint32_t)SDRAM_MODEREG_BURST_LENGTH_4 | SDRAM_MODEREG_BURST_TYPE_SEQUENTIAL
        | SDRAM_MODEREG_CAS_LATENCY_2 | SDRAM_MODEREG_OPERATING_MODE_STANDARD
        | SDRAM_MODEREG_WRITEBURST_MODE_SINGLE;

    Command.CommandMode = FMC_SDRAM_CMD_LOAD_MODE;
    Command.CommandTarget = FMC_SDRAM_CMD_TARGET_BANK1;
    Command.AutoRefreshNumber = 1;
    Command.ModeRegisterDefinition = tmpmrd;

    /* Send the command */
    HAL_SDRAM_SendCommand(&hsdram1, &Command, SDRAM_TIMEOUT);

    /* Step 4: Configure the 1st Auto Refresh command */
    Command.CommandMode = FMC_SDRAM_CMD_AUTOREFRESH_MODE;
    Command.CommandTarget = FMC_SDRAM_CMD_TARGET_BANK1;
    Command.AutoRefreshNumber = 8;
    Command.ModeRegisterDefinition = 0;

    /* Send the command */
    HAL_SDRAM_SendCommand(&hsdram1, &Command, SDRAM_TIMEOUT);

    /* Step 2: Insert 100 us minimum delay */
    /* Inserted delay is equal to 1 ms due to systick time base unit (ms) */
    HAL_Delay(1);

    /* Step 5: Configure the 2nd Auto Refresh command */
    Command.CommandMode = FMC_SDRAM_CMD_AUTOREFRESH_MODE;
    Command.CommandTarget = FMC_SDRAM_CMD_TARGET_BANK1;
    Command.AutoRefreshNumber = 8;
    Command.ModeRegisterDefinition = 0;

    /* Send the command */
    HAL_SDRAM_SendCommand(&hsdram1, &Command, SDRAM_TIMEOUT);

    /* Step 6: Set the refresh rate counter */
    /* Set the device refresh rate */
    HAL_SDRAM_ProgramRefreshRate(&hsdram1, SDRAM_REFRESH_COUNT);
}

#if SDRECORD

volatile FRESULT res2;
uint8_t rtext[100];                                   /* File read buffer */
uint32_t byteswritten, bytesread;                     /* File write/read counts */
uint8_t wtext[220000] __ATTR_RAM_D1; /* File write buffer */
uint32_t wtextPointer = 0;
char tempText[30];
int testNumber = 55559;
char filename[40];
char fileExt[] = ".txt";
static void FS_FileOperations(void)
{
  uint theNumber = randomNumber() * 65535;
  itoa(theNumber,tempText, 10);
  strncat(filename, tempText, sizeof(tempText));
  strncat(filename, fileExt, sizeof(fileExt));
  statusH = disk_initialize(0);
  HAL_Delay(10);
  /* Register the file system object to the FatFs module */
  if(f_mount(&MMCFatFs, (TCHAR const*)SDPath, 1) == FR_OK)
  {
	  {
		  if(f_open(&myFile, filename, FA_CREATE_ALWAYS | FA_WRITE) == FR_OK)
		  {
			SDReady = 1;
		  }
	  }
  }
}

uint8_t comma[] = ", ";
uint8_t newline[] = "\r\n";

void writeSD(void)
{
	if (SDReady == 1)
	{
		int maxPointer = memoryPointer;
		__disable_irq();
		for (int j = 0; j < maxPointer; j++)
		{
			//get number
			int theNumber = (int)largeMemory[j];
			//clear temp text
			for (int i = 0; i < 10; i++)
			{
				tempText[i] = 0;
			}
			itoa(theNumber,tempText, 10);

			//if you don't have room in the temp buffer, write it to the SD card
			if (wtextPointer > (220000 - 20))
			{
				//HAL_GPIO_WritePin(GPIOB, GPIO_PIN_4, GPIO_PIN_SET);

				 f_write(&myFile, wtext, wtextPointer, (void *)&byteswritten);
				 wtextPointer = 0;

			}
			for (int i = 0; i < 5; i++)
			{
				if (tempText[i] != 0)
				{
					wtext[wtextPointer] = tempText[i];
					wtextPointer++;
				}
			}
			if (((j + 1) % 50) == 0)
			{

				wtext[wtextPointer] = 59;
				wtextPointer++;
				wtext[wtextPointer] = 13;
				wtextPointer++;
				wtext[wtextPointer] = 10;

			}
			else
			{
				wtext[wtextPointer] = 32;
			}

			wtextPointer++;

		}
		res2 = f_close(&myFile);

		 HAL_GPIO_WritePin(GPIOB, GPIO_PIN_4, GPIO_PIN_RESET);
		 if (res2 == FR_OK)
		 {
			 HAL_GPIO_WritePin(GPIOB, GPIO_PIN_4, GPIO_PIN_SET);
		 }
		__enable_irq();
	}
}

void writeToSD(int theIndex, int theNumber, int whichString, int value)
{
	if(finishSD == 1)
	{

		SDReady = 0;
		largeMemory[memoryPointer] = 0;
		memoryPointer++;

		//HAL_GPIO_WritePin(GPIOB, GPIO_PIN_4, GPIO_PIN_SET);
		__disable_irq();
		 f_write(&myFile, largeMemory, memoryPointer, (void *)&byteswritten);
		 res2 = f_close(&myFile);
		 __enable_irq();
		 HAL_GPIO_WritePin(GPIOB, GPIO_PIN_4, GPIO_PIN_RESET);
		 if (res2 == FR_OK)
		 {
			 HAL_GPIO_WritePin(GPIOB, GPIO_PIN_4, GPIO_PIN_SET);
		 }

	}
	else if (whichString < 9)
	{

		/*(for (int i = 0; i < 10; i++)
		{
			tempText[i] = 0;
		}
		itoa(theIndex,tempText, 10);
		for (int i = 0; i < 10; i++)
		{
			if (tempText[i] != 0)
			{
				largeMemory[memoryPointer] = tempText[i];
				memoryPointer++;
			}
		}

		largeMemory[memoryPointer] = 44;
		memoryPointer++;
		largeMemory[memoryPointer] = 32;
		memoryPointer++;
*/

		//input value
		for (int i = 0; i < 10; i++)
		{
			tempText[i] = 0;
		}
		itoa(theNumber,tempText, 10);
		for (int i = 0; i < 5; i++)
		{
			if (tempText[i] != 0)
			{
				largeMemory[memoryPointer] = tempText[i];
				memoryPointer++;
			}
		}
		largeMemory[memoryPointer] = 32;
		memoryPointer++;

		//filtered abs
		for (int i = 0; i < 10; i++)
		{
			tempText[i] = 0;
		}
		itoa(tempAbsInt[whichString],tempText, 10);
		for (int i = 0; i < 5; i++)
		{
			if (tempText[i] != 0)
			{
				largeMemory[memoryPointer] = tempText[i];
				memoryPointer++;
			}
		}
		largeMemory[memoryPointer] = 32;
		memoryPointer++;

		//smoothed1
		for (int i = 0; i < 10; i++)
		{
			tempText[i] = 0;
		}
		itoa(smoothedInt[whichString],tempText, 10);
		for (int i = 0; i < 5; i++)
		{
			if (tempText[i] != 0)
			{
				largeMemory[memoryPointer] = tempText[i];
				memoryPointer++;
			}
		}
		largeMemory[memoryPointer] = 32;
		memoryPointer++;

		//smoothed2
		for (int i = 0; i < 10; i++)
		{
			tempText[i] = 0;
		}
		itoa(smoothedInt2[whichString],tempText, 10);
		for (int i = 0; i < 5; i++)
		{
			if (tempText[i] != 0)
			{
				largeMemory[memoryPointer] = tempText[i];
				memoryPointer++;
			}
		}
		largeMemory[memoryPointer] = 32;
		memoryPointer++;

		//smoothed db
		for (int i = 0; i < 10; i++)
		{
			tempText[i] = 0;
		}
		itoa(dbSmoothedInt[whichString],tempText, 10);
		for (int i = 0; i < 5; i++)
		{
			if (tempText[i] != 0)
			{
				largeMemory[memoryPointer] = tempText[i];
				memoryPointer++;
			}
		}
		largeMemory[memoryPointer] = 32;
		memoryPointer++;

		//armed counter
		for (int i = 0; i < 10; i++)
		{
			tempText[i] = 0;
		}
		itoa(armedCounter[whichString],tempText, 10);
		for (int i = 0; i < 5; i++)
		{
			if (tempText[i] != 0)
			{
				largeMemory[memoryPointer] = tempText[i];
				memoryPointer++;
			}
		}
		largeMemory[memoryPointer] = 32;
		memoryPointer++;

		//down counter
		for (int i = 0; i < 10; i++)
		{
			tempText[i] = 0;
		}
		itoa(downCounter[whichString],tempText, 10);
		for (int i = 0; i < 5; i++)
		{
			if (tempText[i] != 0)
			{
				largeMemory[memoryPointer] = tempText[i];
				memoryPointer++;
			}
		}
		largeMemory[memoryPointer] = 32;
		memoryPointer++;

		//string touched
		if (stringTouchRH[whichString] > 0)
		{
			largeMemory[memoryPointer] = 49;

		}
		else
		{
			largeMemory[memoryPointer] = 48;
		}
		memoryPointer++;
		largeMemory[memoryPointer] = 32;
		memoryPointer++;

		//string sounding
		if (stringSounding[whichString] > 0)
		{
			largeMemory[memoryPointer] = 49;

		}
		else
		{
			largeMemory[memoryPointer] = 48;
		}
		memoryPointer++;
		largeMemory[memoryPointer] = 32;
		memoryPointer++;

	}
		/*
		//filtered abs
		for (int i = 0; i < 10; i++)
		{
			tempText[i] = 0;
		}
		itoa(tempAbsInt[whichString],tempText, 10);
		for (int i = 0; i < 5; i++)
		{
			if (tempText[i] != 0)
			{
				largeMemory[memoryPointer] = tempText[i];
				memoryPointer++;
			}
		}
		largeMemory[memoryPointer] = 32;
		memoryPointer++;

		//smoothed1
		for (int i = 0; i < 10; i++)
		{
			tempText[i] = 0;
		}
		itoa(smoothedInt[whichString],tempText, 10);
		for (int i = 0; i < 5; i++)
		{
			if (tempText[i] != 0)
			{
				largeMemory[memoryPointer] = tempText[i];
				memoryPointer++;
			}
		}
		largeMemory[memoryPointer] = 32;
		memoryPointer++;

		//smoothed2
		for (int i = 0; i < 10; i++)
		{
			tempText[i] = 0;
		}
		itoa(smoothedInt2[whichString],tempText, 10);
		for (int i = 0; i < 5; i++)
		{
			if (tempText[i] != 0)
			{
				largeMemory[memoryPointer] = tempText[i];
				memoryPointer++;
			}
		}
		largeMemory[memoryPointer] = 32;
		memoryPointer++;

		//smoothed db
		for (int i = 0; i < 10; i++)
		{
			tempText[i] = 0;
		}
		itoa(dbSmoothedInt[whichString],tempText, 10);
		for (int i = 0; i < 5; i++)
		{
			if (tempText[i] != 0)
			{
				largeMemory[memoryPointer] = tempText[i];
				memoryPointer++;
			}
		}
		largeMemory[memoryPointer] = 32;
		memoryPointer++;

		//didPlucked
		for (int i = 0; i < 10; i++)
		{
			tempText[i] = 0;
		}
		itoa(didPlucked[whichString],tempText, 10);
		for (int i = 0; i < 5; i++)
		{
			if (tempText[i] != 0)
			{
				largeMemory[memoryPointer] = tempText[i];
				memoryPointer++;
			}
		}
		largeMemory[memoryPointer] = 32;
		memoryPointer++;

		//armed counter
		for (int i = 0; i < 10; i++)
		{
			tempText[i] = 0;
		}
		itoa(armedCounter[whichString],tempText, 10);
		for (int i = 0; i < 5; i++)
		{
			if (tempText[i] != 0)
			{
				largeMemory[memoryPointer] = tempText[i];
				memoryPointer++;
			}
		}
		largeMemory[memoryPointer] = 32;
		memoryPointer++;

		//down counter
		for (int i = 0; i < 10; i++)
		{
			tempText[i] = 0;
		}
		itoa(downCounter[whichString],tempText, 10);
		for (int i = 0; i < 5; i++)
		{
			if (tempText[i] != 0)
			{
				largeMemory[memoryPointer] = tempText[i];
				memoryPointer++;
			}
		}
		largeMemory[memoryPointer] = 32;
		memoryPointer++;

		//string Maxes
		for (int i = 0; i < 10; i++)
		{
			tempText[i] = 0;
		}
		itoa(stringMaxes[whichString],tempText, 10);
		for (int i = 0; i < 5; i++)
		{
			if (tempText[i] != 0)
			{
				largeMemory[memoryPointer] = tempText[i];
				memoryPointer++;
			}
		}
		largeMemory[memoryPointer] = 32;
		memoryPointer++;

		//string touched
		if (stringTouchRH[whichString] > 0)
		{
			largeMemory[memoryPointer] = 49;

		}
		else
		{
			largeMemory[memoryPointer] = 48;
		}
		memoryPointer++;
		largeMemory[memoryPointer] = 32;
		memoryPointer++;

		//string sounding
		if (stringSounding[whichString] > 0)
		{
			largeMemory[memoryPointer] = 49;

		}
		else
		{
			largeMemory[memoryPointer] = 48;
		}
		memoryPointer++;
		largeMemory[memoryPointer] = 32;
		memoryPointer++;

		//end
		largeMemory[memoryPointer] = 59;
		memoryPointer++;
		largeMemory[memoryPointer] = 13;
		memoryPointer++;
		largeMemory[memoryPointer] = 10;
		memoryPointer++;

		SDWriteIndex++;

		for (int i = 0; i < 10; i++)
		{
			tempText[i] = 0;
		}
		itoa(myPos,tempText, 10);
		for (int i = 0; i < 10; i++)
		{
			if (tempText[i] != 0)
			{
				largeMemory[memoryPointer] = tempText[i];
				memoryPointer++;
			}
		}
		largeMemory[memoryPointer] = 32;
		memoryPointer++;

		for (int i = 0; i < 10; i++)
		{
			tempText[i] = 0;
		}

		itoa(lh,tempText, 10);
		for (int i = 0; i < 10; i++)
		{
			if (tempText[i] != 0)
			{
				largeMemory[memoryPointer] = tempText[i];
				memoryPointer++;
			}
		}
		largeMemory[memoryPointer] = 32;
		memoryPointer++;

		for (int i = 0; i < 30; i++)
		{
			tempText[i] = 0;
		}
		itoa(rh,tempText, 10);
		for (int i = 0; i < 10; i++)
		{
			if (tempText[i] != 0)
			{
				largeMemory[memoryPointer] = tempText[i];
				memoryPointer++;
			}
		}
		largeMemory[memoryPointer] = 32;
		memoryPointer++;
	}

	else if ((whichString > 0) && (whichString < 3))
	{
		for (int i = 0; i < 30; i++)
		{
			tempText[i] = 0;
		}
		itoa(theNumber,tempText, 10);
		for (int i = 0; i < 10; i++)
		{
			if (tempText[i] != 0)
			{
				largeMemory[memoryPointer] = tempText[i];
				memoryPointer++;
			}
		}
		largeMemory[memoryPointer] = 32;
		memoryPointer++;

		for (int i = 0; i < 10; i++)
		{
			tempText[i] = 0;
		}
		itoa(didPlucked,tempText, 10);
		for (int i = 0; i < 5; i++)
		{
			if (tempText[i] != 0)
			{
				largeMemory[memoryPointer] = tempText[i];
				memoryPointer++;
			}
		}
		largeMemory[memoryPointer] = 32;
		memoryPointer++;

		for (int i = 0; i < 10; i++)
		{
			tempText[i] = 0;
		}
		itoa(myPos,tempText, 10);
		for (int i = 0; i < 10; i++)
		{
			if (tempText[i] != 0)
			{
				largeMemory[memoryPointer] = tempText[i];
				memoryPointer++;
			}
		}
		largeMemory[memoryPointer] = 32;
		memoryPointer++;

		for (int i = 0; i < 10; i++)
		{
			tempText[i] = 0;
		}
		itoa(lh,tempText, 10);
		for (int i = 0; i < 10; i++)
		{
			if (tempText[i] != 0)
			{
				largeMemory[memoryPointer] = tempText[i];
				memoryPointer++;
			}
		}
		largeMemory[memoryPointer] = 32;
		memoryPointer++;

		for (int i = 0; i < 30; i++)
		{
			tempText[i] = 0;
		}
		itoa(rh,tempText, 10);
		for (int i = 0; i < 10; i++)
		{
			if (tempText[i] != 0)
			{
				largeMemory[memoryPointer] = tempText[i];
				memoryPointer++;
			}
		}
		largeMemory[memoryPointer] = 32;
		memoryPointer++;

	}
*/
	else
	{
		for (int i = 0; i < 10; i++)
		{
			tempText[i] = 0;
		}
		itoa(theNumber,tempText, 10);
		for (int i = 0; i < 10; i++)
		{
			if (tempText[i] != 0)
			{
				largeMemory[memoryPointer] = tempText[i];
				memoryPointer++;
			}
		}
		largeMemory[memoryPointer] = 32;
		memoryPointer++;

		//filtered abs
		for (int i = 0; i < 10; i++)
		{
			tempText[i] = 0;
		}
		itoa(tempAbsInt[whichString],tempText, 10);
		for (int i = 0; i < 5; i++)
		{
			if (tempText[i] != 0)
			{
				largeMemory[memoryPointer] = tempText[i];
				memoryPointer++;
			}
		}
		largeMemory[memoryPointer] = 32;
		memoryPointer++;

		//smoothed1
		for (int i = 0; i < 10; i++)
		{
			tempText[i] = 0;
		}
		itoa(smoothedInt[whichString],tempText, 10);
		for (int i = 0; i < 5; i++)
		{
			if (tempText[i] != 0)
			{
				largeMemory[memoryPointer] = tempText[i];
				memoryPointer++;
			}
		}
		largeMemory[memoryPointer] = 32;
		memoryPointer++;

		//smoothed2
		for (int i = 0; i < 10; i++)
		{
			tempText[i] = 0;
		}
		itoa(smoothedInt2[whichString],tempText, 10);
		for (int i = 0; i < 5; i++)
		{
			if (tempText[i] != 0)
			{
				largeMemory[memoryPointer] = tempText[i];
				memoryPointer++;
			}
		}
		largeMemory[memoryPointer] = 32;
		memoryPointer++;

		//smoothed db
		for (int i = 0; i < 10; i++)
		{
			tempText[i] = 0;
		}
		itoa(dbSmoothedInt[whichString],tempText, 10);
		for (int i = 0; i < 5; i++)
		{
			if (tempText[i] != 0)
			{
				largeMemory[memoryPointer] = tempText[i];
				memoryPointer++;
			}
		}
		largeMemory[memoryPointer] = 32;
		memoryPointer++;

		//armed counter
		for (int i = 0; i < 10; i++)
		{
			tempText[i] = 0;
		}
		itoa(armedCounter[whichString],tempText, 10);
		for (int i = 0; i < 5; i++)
		{
			if (tempText[i] != 0)
			{
				largeMemory[memoryPointer] = tempText[i];
				memoryPointer++;
			}
		}
		largeMemory[memoryPointer] = 32;
		memoryPointer++;

		//down counter
		for (int i = 0; i < 10; i++)
		{
			tempText[i] = 0;
		}
		itoa(downCounter[whichString],tempText, 10);
		for (int i = 0; i < 5; i++)
		{
			if (tempText[i] != 0)
			{
				largeMemory[memoryPointer] = tempText[i];
				memoryPointer++;
			}
		}
		largeMemory[memoryPointer] = 32;
		memoryPointer++;

		//string touched
		if (stringTouchRH[whichString] > 0)
		{
			largeMemory[memoryPointer] = 49;

		}
		else
		{
			largeMemory[memoryPointer] = 48;
		}
		memoryPointer++;
		largeMemory[memoryPointer] = 32;
		memoryPointer++;

		//string sounding
		if (stringSounding[whichString] > 0)
		{
			largeMemory[memoryPointer] = 49;

		}
		else
		{
			largeMemory[memoryPointer] = 48;
		}
		memoryPointer++;
		largeMemory[memoryPointer] = 59;
		memoryPointer++;
		largeMemory[memoryPointer] = 13;
		memoryPointer++;
		largeMemory[memoryPointer] = 10;
		memoryPointer++;
	}
/*
		for (int i = 0; i < 10; i++)
		{
			tempText[i] = 0;
		}
		itoa(myPos,tempText, 10);
		for (int i = 0; i < 10; i++)
		{
			if (tempText[i] != 0)
			{
				largeMemory[memoryPointer] = tempText[i];
				memoryPointer++;
			}
		}
		largeMemory[memoryPointer] = 32;
		memoryPointer++;

		for (int i = 0; i < 10; i++)
		{
			tempText[i] = 0;
		}
		itoa(lh,tempText, 10);
		for (int i = 0; i < 10; i++)
		{
			if (tempText[i] != 0)
			{
				largeMemory[memoryPointer] = tempText[i];
				memoryPointer++;
			}
		}
		largeMemory[memoryPointer] = 32;
		memoryPointer++;

		for (int i = 0; i < 30; i++)
		{
			tempText[i] = 0;
		}
		itoa(rh,tempText, 10);
		for (int i = 0; i < 10; i++)
		{
			if (tempText[i] != 0)
			{
				largeMemory[memoryPointer] = tempText[i];
				memoryPointer++;
			}
		}
		largeMemory[memoryPointer] = 32;
		memoryPointer++;

		largeMemory[memoryPointer] = 59;
		memoryPointer++;
		largeMemory[memoryPointer] = 13;
		memoryPointer++;
		largeMemory[memoryPointer] = 10;
		memoryPointer++;

		SDWriteIndex++;
	}
	*/
}
#endif

void MPU_Conf(void)
 {
	//code from Keshikan https://github.com/keshikan/STM32H7_DMA_sample
  //Thanks, Keshikan! This solves the issues with accessing the SRAM in the D2 area properly. -JS
	//should test the different possible settings to see what works best while avoiding needing to manually clear the cache -JS

	MPU_Region_InitTypeDef MPU_InitStruct;

	  HAL_MPU_Disable();

	  MPU_InitStruct.Enable = MPU_REGION_ENABLE;

	  //D2 Domain�SRAM1
	  MPU_InitStruct.BaseAddress = 0x30000000;
	  // Increased region size to 256k. In Keshikan's code, this was 512 bytes (that's all that application needed).
	  // Each audio buffer takes up the frame size * 8 (16 bits makes it *2 and stereo makes it *2 and double buffering makes it *2)
	  // So a buffer size for read/write of 4096 would take up 64k = 4096*8 * 2 (read and write).
	  // I increased that to 256k so that there would be room for the ADC knob inputs and other peripherals that might require DMA access.
	  // we have a total of 256k in SRAM1 (128k, 0x30000000-0x30020000) and SRAM2 (128k, 0x30020000-0x3004000) of D2 domain.
	  // There is an SRAM3 in D2 domain as well (32k, 0x30040000-0x3004800) that is currently not mapped by the MPU (memory protection unit) controller.

	  MPU_InitStruct.Size = MPU_REGION_SIZE_256KB;

	  MPU_InitStruct.AccessPermission = MPU_REGION_FULL_ACCESS;

	  //AN4838
	  MPU_InitStruct.TypeExtField = MPU_TEX_LEVEL1;
	  MPU_InitStruct.IsCacheable = MPU_ACCESS_NOT_CACHEABLE;
	  MPU_InitStruct.IsBufferable = MPU_ACCESS_NOT_BUFFERABLE;
	  MPU_InitStruct.IsShareable = MPU_ACCESS_NOT_SHAREABLE;

	  //Shared Device
//	  MPU_InitStruct.TypeExtField = MPU_TEX_LEVEL0;
//	  MPU_InitStruct.IsCacheable = MPU_ACCESS_NOT_CACHEABLE;
//	  MPU_InitStruct.IsBufferable = MPU_ACCESS_BUFFERABLE;
//	  MPU_InitStruct.IsShareable = MPU_ACCESS_SHAREABLE;

	  MPU_InitStruct.Number = MPU_REGION_NUMBER0;

	  MPU_InitStruct.SubRegionDisable = 0x00;

	  MPU_InitStruct.DisableExec = MPU_INSTRUCTION_ACCESS_DISABLE;

	  HAL_MPU_ConfigRegion(&MPU_InitStruct);

	  //now set up D3 domain RAM

	  MPU_InitStruct.Enable = MPU_REGION_ENABLE;

	  //D3 Domain�SRAM
	  MPU_InitStruct.BaseAddress = 0x38000000;

	  MPU_InitStruct.Size = MPU_REGION_SIZE_64KB;

	  MPU_InitStruct.AccessPermission = MPU_REGION_FULL_ACCESS;

	  //AN4838
	  MPU_InitStruct.TypeExtField = MPU_TEX_LEVEL1;
	  MPU_InitStruct.IsCacheable = MPU_ACCESS_CACHEABLE;
	  MPU_InitStruct.IsBufferable = MPU_ACCESS_BUFFERABLE;
	  MPU_InitStruct.IsShareable = MPU_ACCESS_SHAREABLE;

	  //Shared Device
 //	  MPU_InitStruct.TypeExtField = MPU_TEX_LEVEL0;
 //	  MPU_InitStruct.IsCacheable = MPU_ACCESS_NOT_CACHEABLE;
 //	  MPU_InitStruct.IsBufferable = MPU_ACCESS_BUFFERABLE;
 //	  MPU_InitStruct.IsShareable = MPU_ACCESS_SHAREABLE;

	  MPU_InitStruct.Number = MPU_REGION_NUMBER1;

	  MPU_InitStruct.SubRegionDisable = 0x00;

	  MPU_InitStruct.DisableExec = MPU_INSTRUCTION_ACCESS_ENABLE;

	  HAL_MPU_ConfigRegion(&MPU_InitStruct);

	  HAL_MPU_Enable(MPU_PRIVILEGED_DEFAULT);
}

volatile int totalMaximums[NUM_STRINGS];
volatile float pickupMaximums[NUM_STRINGS] = {0.0f, 0.0f, 0.0f, 0.0f};
int attackDetectPeak2 (int whichString, int tempInt)
{
	float output = -1;
	float tempSamp = (((float)tempInt - TWO_TO_15) * INV_TWO_TO_15);
	for (int k = 0; k < FILTER_ORDER; k++)
	{
		// a highpass filter, remove any slow moving signal (effectively centers the signal around zero and gets rid of the signal that isn't high frequency vibration) cutoff of 100Hz, // applied 8 times to get rid of a lot of low frequency bumbling around
		tempSamp = tHighpass_tick(&opticalHighpass[whichString][k], tempSamp);
		tempSamp = tVZFilter_tickEfficient(&opticalLowpass[whichString][k], tempSamp);
	}

	float tempAbs = fabsf(tempSamp);
	tempAbsInt[whichString] = (tempAbs * (TWO_TO_16 - 1));
	Dsmoothed = tSlide_tick(&fastSlide[whichString], tempAbs);
	smoothedInt[whichString] = (Dsmoothed * (TWO_TO_16 - 1));
	Dsmoothed2 = tSlide_tick(&slowSlide[whichString], Dsmoothed);

	Dsmoothed2 = LEAF_clip(0.0f, Dsmoothed2, 1.0f);
	smoothedInt2[whichString] = (Dsmoothed2 * (TWO_TO_16 - 1));
	//dbSmoothed2 = atodb(Dsmoothed2);
	dbSmoothed2 = LEAF_clip(-60.0f, atodbTable[(uint32_t)(Dsmoothed2 * ATODB_TABLE_SIZE_MINUS_ONE)], 12.0f);
	dbSmoothedInt[whichString] = dbSmoothed2 * 100.0f;
	//dbSmoothed2 = LEAF_clip(-50.f, dbSmoothed2, 12.0f);
	//get the slope
	float slope = (dbSmoothed2 - prevdbSmoothed2[whichString]);
	slopeStorage[whichString] = slope;
	float integerVersion = Dsmoothed2 * (TWO_TO_16 - 1);
	threshOut = tThreshold_tick(&threshold[whichString], integerVersion);
	if ((slope > 0.05f) && (threshOut > 0))
	{
		armed[whichString] = 1;
		pickupMaximums[whichString] = 0.0f;
		if (whichString == 1)
		{
			HAL_GPIO_WritePin(GPIOB, GPIO_PIN_6, GPIO_PIN_SET);
		}
	}

	if (armed[whichString] == 1)
	{
		if (integerVersion > stringMaxes[whichString])
		{
			stringMaxes[whichString] = integerVersion;
		}
		armedCounter[whichString]++;

		if (slope <= 0.0f)
		{
			downCounter[whichString]++;
			if (whichString == 1)
			{
				//HAL_GPIO_WritePin(GPIOB, GPIO_PIN_8, GPIO_PIN_SET);
			}
		}
		if (slope > 0.01f)
		{
			downCounter[whichString] = 0;
			if (whichString == 1)
			{
				//HAL_GPIO_WritePin(GPIOB, GPIO_PIN_8, GPIO_PIN_RESET);
			}
		}
		if (downCounter[whichString] > 128)
		{
			//found a peak?
			//output = stringMaxes[whichString];
			output = pickupMaximums[whichString] * 65535.0f;

			output = LEAF_clip(0.0f, output, 65535.0f);
			armed[whichString] = 0;
			armedCounter[whichString] = 0;
			downCounter[whichString] = 0;
			stringMaxes[whichString] = 0;
			if (whichString == 1)
			{
				HAL_GPIO_WritePin(GPIOB, GPIO_PIN_6, GPIO_PIN_RESET);
			}

		}
	}

	prevdbSmoothed2[whichString] = dbSmoothed2;
	return (int)output;
}

int stringStates[4];
uint16_t stringPressed[4];
int spiBuffer = 0;
int didPluckedWaiting[4] = {0,0,0,0};
int didPluckedWaitingCounter[4] = {0,0,0,0};
void ADC_Frame(int offset)
{
	//HAL_GPIO_TogglePin(GPIOG, GPIO_PIN_11);
	//HAL_GPIO_WritePin(GPIOA, GPIO_PIN_9, GPIO_PIN_SET);
	int changeHappened = 0;
	//sampRecords[currentSamp] = frameCount;
	//currentSamp++;

	for (int i = offset; i < ADC_FRAME_SIZE + offset; i++)
	{
		//for (int j = 0; j < NUM_ADC_CHANNELS; j++)
		if (howManyFrames > 0)
		{
			howManyFrames--;
		}
		for (int j = 0; j < 4; j++)
		{
			int tempInt = ADC_values[(i*NUM_ADC_CHANNELS) + j];

			didPlucked[j] = attackDetectPeak2(j, tempInt);

			//stringTouchRH[j] = (SPI_RX[(16*spiBuffer) + 8] >> (j+4)) & 1;
			//stringTouchLH[j] = (SPI_RX[(16*spiBuffer) + 8] >> j) & 1;
			//int currentnumber = (j*2) + (16*spiBuffer);
			//stringPressed[j] = (SPI_RX[currentnumber] << 8) + SPI_RX[currentnumber+1];

			/*
			if (didPlucked2[j] < 0)
			{
				didPlucked2[j] = 0;
			}
			//didPlucked2[j] = tPluckDetectorInt_tick(&myPluck[j], tempInt);
			if (didPlucked[j] < 0)
			{
				didPlucked[j] = 0;
			}
			*/
			/*
			else if (didPlucked[j] > 0)
			{
				pluckDelay[j] = 1;
				pluckValues[j] = didPlucked[j];
			}

			int doIt = 0;
*/
			if (howManyFrames == 0)
			{
				/*
				if (pluckDelay[j] > 128)
				{
					doIt = 1;
					pluckDelay[j] = 0;
				}
				if (pluckDelay[j] > 0)
				{
					pluckDelay[j]++;
				}
*/

				//if (stringTouchLH[j] || stringTouchRH[j])
				//{
					//HAL_GPIO_WritePin(GPIOB, GPIO_PIN_4, GPIO_PIN_SET);
				//}
				int LHmuted = 0;
				HAL_GPIO_WritePin(GPIOB, GPIO_PIN_8, (GPIO_PinState) stringTouchRH[1]);
				if (stringTouchLH[j] && (stringPressed[j] == 65535))
				{
					LHmuted = 1;
				}
				else
				{
					LHmuted = 0;
				}

				if (((didPlucked[j] > 0) && (!stringSounding[j])) && ((stringTouchRH[j]) || (LHmuted)))
				{
					//got an attack but string is muted, hold this for a ms in case the touch sensor data is coming a little late
					didPluckedWaiting[j] = didPlucked[j];
					didPluckedWaitingCounter[j] = 500;
				}
				if (didPluckedWaitingCounter[j] == 0)
				{
					didPluckedWaiting[j] = -1;
				}
				if ((didPluckedWaiting[j] >= didPlucked[j]) && (didPluckedWaitingCounter[j] > 0))
				{
					didPlucked[j] = didPluckedWaiting[j];
					didPluckedWaitingCounter[j]--;
				}
				else
				{
					didPluckedWaiting[j] = 0;
				}

				if (((didPlucked[j] > 0)) && (!stringSounding[j]) && (!stringTouchRH[j]) && (!LHmuted))
				{
					if (didPlucked[j] > totalMaximums[j])
					{
						totalMaximums[j] = didPlucked[j];
					}
					//didPlucked[j] = (float)didPlucked[j];// * storedMaxFloats[j];
					if (didPlucked[j] > 65535)
					{
						didPlucked[j] = 65535;
					}
					stringStates[j] = didPlucked[j];
					//SPI_PLUCK_TX[(j * 2)] = (didPlucked[j] >> 8);
					//SPI_PLUCK_TX[(j * 2)] = (didPlucked[j] & 0xff);

					//a pluck happened! send a message over SPI to the other ICs
					//TODO: a pluck message

					if (j == 1)
					{
						HAL_GPIO_WritePin(GPIOG, GPIO_PIN_10, GPIO_PIN_SET);

					}
					//SPI_TX[j*2+(16*spiBuffer)] = (uint8_t) (didPlucked[j] >> 8); //high byte
					//SPI_TX[j*2+1+(16*spiBuffer)] = (uint8_t) (didPlucked[j] & 0xff); //low byte

					//HAL_SPI_Transmit_DMA(&hspi1, SPI_PLUCK_TX, 20);
					/*
					SPI_PLUCK_TX[0] = j;
					SPI_PLUCK_TX[1] = (uint8_t) (didPlucked[j] >> 8); //high byte
					SPI_PLUCK_TX[2] = (uint8_t) (didPlucked[j] & 0xff); //low byte
					SPI_PLUCK_TX[3] = 0;
					*/
					changeHappened = 1;
					stringSounding[j] = 1;
					//HAL_SPI_Transmit_DMA(&hspi1, SPI_PLUCK_TX, 4);
				}

				if (((stringTouchRH[j]) && (stringSounding[j])) || (LHmuted && stringSounding[j]))
				{
					//a note-off happened! send a message over SPI to the other ICs
					/*
					SPI_PLUCK_TX[0] = j;
					SPI_PLUCK_TX[1] = 0;
					SPI_PLUCK_TX[2] = 0;
					SPI_PLUCK_TX[3] = 0;
					*/
					//SPI_PLUCK_TX[(j * 2)] = 0;
					//SPI_PLUCK_TX[(j * 2)] = 0;
					//SPI_TX[j*2+(16*spiBuffer)] = 0;
					//SPI_TX[j*2+1+(16*spiBuffer)] = 0;
					if (j == 1)
					{
						HAL_GPIO_WritePin(GPIOG, GPIO_PIN_10, GPIO_PIN_RESET);

					}
					//HAL_SPI_Transmit_DMA(&hspi1, SPI_PLUCK_TX, 20);
					stringStates[j] = 0;
					changeHappened = 1;
					pickupMaximums[j] = 0.0f;
					stringSounding[j] = 0;
				}
				#if SDRECORD
				if (SDReady)
				{
					writeToSD(SDWriteIndex, tempInt, j, stringSounding[j]);

					if (memoryPointer >= ((LARGE_MEM_SIZE/2) - 3000))
					{
						finishSD = 1;
						HAL_ADC_Stop(&hadc1);
						//HAL_SAI_DMAStop(&hsai_BlockA1);
						//HAL_SAI_DMAStop(&hsai_BlockB1);
					}
				}
				#endif
/*
				if (memoryPointer < ((LARGE_MEM_SIZE / 2) - 10))
				{
					largeMemory[memoryPointer++] = (uint16_t)tempInt;
					largeMemory[memoryPointer++] = (uint16_t)didPlucked[j];
					largeMemory[memoryPointer++] = (uint16_t)(myPluck[j]->ready_for_pluck);
					largeMemory[memoryPointer++] = (uint16_t)(myPluck[j]->midpoint_estimate);
					largeMemory[memoryPointer++] = (uint16_t)didPlucked2[j];
					largeMemory[memoryPointer++] = (uint16_t)armed[j];
					largeMemory[memoryPointer++] = (uint16_t)downCounter[j];
					largeMemory[memoryPointer++] = (uint16_t)((slopeStorage[j] * 4096.0f) + 2048.0f);
					largeMemory[memoryPointer++] = (uint16_t)stringTouchRH[j];
					largeMemory[memoryPointer++] = (uint16_t)stringSounding[j];
				}
				else
				{
					writeSD();

					while(1)
					{
						//HAL_GPIO_WritePin(GPIOB, GPIO_PIN_4, GPIO_PIN_SET);
					}
				}

*/
			}
			//itoa(SDWriteIndex, wtext, 4);

		}

	}
	//HAL_GPIO_WritePin(GPIOA, GPIO_PIN_9, GPIO_PIN_RESET);
	if (changeHappened)
	{
		//HAL_SPI_Transmit_DMA(&hspi1, SPI_PLUCK_TX, 22);
	}
}

void ADC_EM(int offset)
{
	for (int i = offset; i < ADC_FRAME_SIZE + offset; i++)
	{
		for (int j = 0; j < NUM_ADC_CHANNELS2; j++)
		{
			int tempInt = ADC_values2[(i*NUM_ADC_CHANNELS2) + j];
			float tempSamp = (((float)tempInt - TWO_TO_15) * INV_TWO_TO_15) * 2.5f;
			tempSamp = tHighpass_tick(&EMHighpass[j], tempSamp);
			float absFloat = fabsf(tempSamp);
			if (absFloat > pickupMaximums[j])
			{
				pickupMaximums[j] = absFloat;
			}

		}
	}
}
void HAL_ADC_ConvCpltCallback(ADC_HandleTypeDef *hadc)
{

	if (hadc == &hadc1)
	{
		ADC_Frame(ADC_FRAME_SIZE);
	}
	else
	{
		ADC_EM(ADC_FRAME_SIZE);
	}

}
void HAL_ADC_ConvHalfCpltCallback(ADC_HandleTypeDef *hadc)
{
	if (hadc == &hadc1)
	{
		ADC_Frame(0);
	}
	else
	{
		ADC_EM(0);
	}
}
void HAL_ADC_Error(ADC_HandleTypeDef *hadc)
{

}

void HAL_SPI_TxRxCpltCallback(SPI_HandleTypeDef *hspi)
{
	spiBuffer = 1;
	//HAL_GPIO_WritePin(GPIOB, GPIO_PIN_4, GPIO_PIN_RESET);

	for (int j = 0; j < 4; j++)
	{
		stringTouchRH[j] = (SPI_RX[24] >> (j+4)) & 1;
		stringTouchLH[j] = (SPI_RX[24] >> j) & 1;
		int currentnumber = (j*2) + 16;
		stringPressed[j] = (SPI_RX[currentnumber] << 8) + SPI_RX[currentnumber+1];
		//if (stringTouchLH[j] || stringTouchRH[j])
		//{
			//HAL_GPIO_WritePin(GPIOB, GPIO_PIN_4, GPIO_PIN_SET);
		//}

		SPI_TX[j*2+(16*spiBuffer)] = (uint8_t) (stringStates[j] >> 8); //high byte
		SPI_TX[j*2+1+(16*spiBuffer)] = (uint8_t) (stringStates[j] & 0xff); //low byte
	}
	//HAL_GPIO_WritePin(GPIOG, GPIO_PIN_10, GPIO_PIN_RESET);

}

void HAL_SPI_TxRxHalfCpltCallback(SPI_HandleTypeDef *hspi)
{
	//HAL_GPIO_WritePin(GPIOB, GPIO_PIN_4, GPIO_PIN_RESET);
	spiBuffer = 0;

	for (int j = 0; j < 4; j++)
	{
		stringTouchRH[j] = (SPI_RX[8] >> (j+4)) & 1;
		stringTouchLH[j] = (SPI_RX[8] >> j) & 1;
		stringPressed[j] = (SPI_RX[j*2] << 8) + SPI_RX[(j*2)+1];
		//if (stringTouchLH[j] || stringTouchRH[j])
		//{
			//HAL_GPIO_WritePin(GPIOB, GPIO_PIN_4, GPIO_PIN_SET);
		//}
		SPI_TX[j*2+(16*spiBuffer)] = (uint8_t) (stringStates[j] >> 8); //high byte
		SPI_TX[j*2+1+(16*spiBuffer)] = (uint8_t) (stringStates[j] & 0xff); //low byte
	}
	//HAL_GPIO_WritePin(GPIOG, GPIO_PIN_10, GPIO_PIN_SET);
}

void HAL_SAI_RxCpltCallback(SAI_HandleTypeDef *hsai)
{
	HAL_GPIO_WritePin(GPIOA, GPIO_PIN_11, GPIO_PIN_SET);
	int buffer_offset = HALF_BUFFER_SIZE;
	for (int i = 0; i < (HALF_BUFFER_SIZE); i += 2)
	{
		float theSamples[2];
		theSamples[0] = ((float)audioInBuffer[buffer_offset + i]) * INV_TWO_TO_31;
		theSamples[1] = ((float)audioInBuffer[buffer_offset + i + 1]) * INV_TWO_TO_31;
		float absFloat = fabsf(theSamples[0]);
		if (absFloat > pickupMaximums[2])
		{
			pickupMaximums[2] = absFloat;
		}
		absFloat = fabsf(theSamples[1]);
		if (absFloat > pickupMaximums[3])
		{
			pickupMaximums[3] = absFloat;
		}
		audioOutBuffer[buffer_offset + i] = (int32_t)(theSamples[1] * TWO_TO_31);
		audioOutBuffer[buffer_offset + i + 1] = (int32_t)(theSamples[0] * TWO_TO_31);
	}

}

volatile int myTest = 0;
volatile float theSamples[2];
void HAL_SAI_RxHalfCpltCallback(SAI_HandleTypeDef *hsai)
{
	HAL_GPIO_WritePin(GPIOA, GPIO_PIN_11, GPIO_PIN_RESET);
	int buffer_offset = 0;
	for (int i = 0; i < (HALF_BUFFER_SIZE); i += 2)
	{

		theSamples[0] = ((float)audioInBuffer[buffer_offset + i]) * INV_TWO_TO_31;
		theSamples[1] = ((float)audioInBuffer[buffer_offset + i + 1]) * INV_TWO_TO_31;

		float absFloat = fabsf(theSamples[0]);
		if (absFloat > pickupMaximums[2])
		{
			pickupMaximums[2] = absFloat;
		}
		absFloat = fabsf(theSamples[1]);
		if (absFloat > pickupMaximums[3])
		{
			pickupMaximums[3] = absFloat;
			if (pickupMaximums[3] > 0.99f)
			{
				myTest = 1;
			}
		}

		audioOutBuffer[buffer_offset + i] = (int32_t)(theSamples[1] * TWO_TO_31);
		audioOutBuffer[buffer_offset + i + 1] = (int32_t)(theSamples[0] * TWO_TO_31);
	}

}

/* USER CODE END 4 */

void Error_Handler(void)
{
}

/************************ (C) COPYRIGHT STMicroelectronics *****END OF FILE****/
